# A33G53x register map
Vendor: ABOV Semiconductor Co., Ltd.; File version: 0.1
CPU: CM3 r1p0, little endian, no MPU, no FPU, 3 interrupt priority bits
Registers are 32-bit, read-write, reset 0x0 unless marked. A register's access mark holds for its fields unless they carry their own. Offsets are from the block's base; [hi:lo] are bit positions; {n}, {i} and the like mark numbered series.

## UART0 — UNIVERSAL ASYNCHRONOUS RECEIVER/TRANSMITTER
Base 0x40000B00
Same registers: UART1 0x40000B40, UART2 0x40000B80, UART3 0x40000BC0
0x00 RBR — Rx Buffer REGISTER
  [7:0] RBR — Received data byte
0x00 THR (alternate view of RBR) — Tx Buffer REGISTER
  [7:0] THR — Data byte to be transmitted
0x00 DLL (alternate view of RBR) — UART n Divisor Latch Register LSB
  [7:0] DLL
0x04 DLM (reset mask 0xF) — UART n Divisor Latch Register MSB
  [7:0] DLM
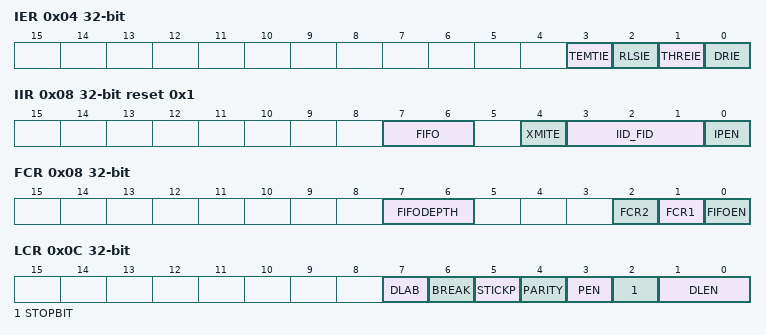
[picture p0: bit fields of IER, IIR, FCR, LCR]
0x04 IER (alternate view of DLM) — UART Interrupt Enable Register
  [3] TEMTIE — Transmission empty interrupt enable
  [2] RLSIE — receiver line status interrupt enable
  [1] THREIE — Transmit holding register empty interrupt enable
  [0] DRIE — Data Ready Interrupt Enable/Disable
0x08 IIR ro reset 0x1 (reset mask 0xCF) — UART Interrupt ID Register
  [7:6] FIFO — Current UART operation FIFO mode
  [4] XMITE — Transmit empty interrupt check
  [3:1] IID_FID — Interrupt source ID
  [0] IPEN — Interrupt pending bit
0x08 FCR wo — FIFO Control Register
  [7:6] FIFODEPTH — Receive FIFO trigger level
  [2] FCR2 — Initialize transmit FIFO
  [1] FCR1 — Initialize receive FIFO
  [0] FIFOEN — Enable transmit/receive FIFO
0x0C LCR — UART Line Control Register
  [7] DLAB — Norma Transmission-Divisor Latch Access Mode
  [6] BREAK — Normal Transmission-Send Break
  [5] STICKP — Stick Parity as L-H
  [4] PARITY — OddEven Parity
  [3] PEN — Enable Parity
  [2] STOPBIT — 1-(1.5,2) stop bits
  [1:0] DLEN — Data length in one transfer word
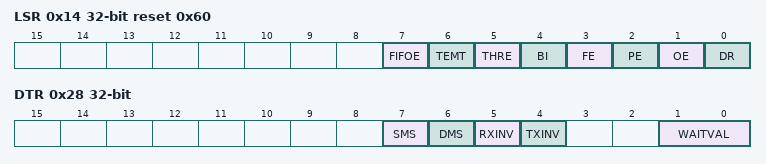
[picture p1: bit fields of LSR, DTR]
0x14 LSR reset 0x60 — UART Line Status Register
  [7] FIFOE ro — FIFO has invalid data
  [6] TEMT ro — Transmitter Empty
  [5] THRE ro — THR Empty
  [4] BI ro — break condition indication bit
  [3] FE ro — frame error
  [2] PE ro — parity error
  [1] OE ro — overrun error
  [0] DR ro — Data recevied
0x1C SCR — UART Scratch Register
  [7:0] SCR — This register is used to store a data temporarily by software programmer
0x24 BFR — UART BaudRate Fraction Counter Register
  [7:0] BFR — This 8-bit register is used to increase the accuracy of the baud rate.
0x28 DTR — UART Inter-frame Delay Time Register
  [7] SMS — Performs sampling of the start bit
  [6] DMS — Performs sampling of the Data bit
  [5] RXINV — Change / maintain external RX input
  [4] TXINV — Change / maintain TX Output
  [1:0] WAITVAL — Sets the delay time between successive data outputs

## SPI0 — SERIAL PERIPHERAL INTERFACE
Base 0x40000800
Same registers: SPI1 0x40000820
0x00 TDR — SPI n Transmit Data Register
  [16:0] TDR — Transmit Data Value
0x00 RDR (alternate view of TDR) — SPI n Receive Data Register
  [16:0] RDR — Receive Data Value
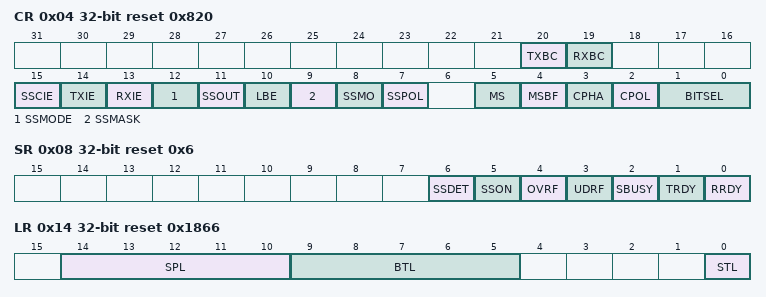
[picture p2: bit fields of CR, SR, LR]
0x04 CR reset 0x820 — SPI n Control Register
  [20] TXBC — TX BUFFER CLEAR
  [19] RXBC — RX BUFFER CLEAR
  [15] SSCIE — SSn Edge Chagne Interrupt enable bit
  [14] TXIE — Transmit interrupt enable bit
  [13] RXIE — Receive interrupt enable bit
  [12] SSMODE — SS Auto/Manual Output select bit
  [11] SSOUT — SS output signal select bit
  [10] LBE — Loop-back mode select bit in master mode
  [9] SSMASK — SS Signal masking bit in slave mode
  [8] SSMO — SS output signal select bit
  [7] SSPOL — SS Signal polarity select bit
  [5] MS — master/slaver select bit
  [4] MSBF — MSB/LSB transmit select bit
  [3] CPHA — SPI clock phase bit
  [2] CPOL — SPI clock polarity bit
  [1:0] BITSEL — Transmit/receive Data bits select bit
0x08 SR reset 0x6 — SPI n Status Register
  [6] SSDET — The rising edge of SS detect flag
  [5] SSON ro — SS signal status flag
  [4] OVRF — receive overrun error flag
  [3] UDRF — transmit underrun error flag
  [2] SBUSY ro — transmit/receive operation flag
  [1] TRDY ro — Transmit buffer empty flag
  [0] RRDY ro — receive buffer ready flag
0x0C BR — SPI n Baud Rate Register
  [7:0] BR — buadrate
0x10 EN — SPI n Enable register
  [0] ENABLE — SPI ENABLE bit
0x14 LR reset 0x1866 (reset mask 0x1FFF) — SPI n Timing register
  [14:10] SPL — Stop delay time setting
  [9:5] BTL — Burst delay time setting
  [0] STL — Start delay time setting

## ADC — 12-BIT A/D CONVERTER
Base 0x40000E00
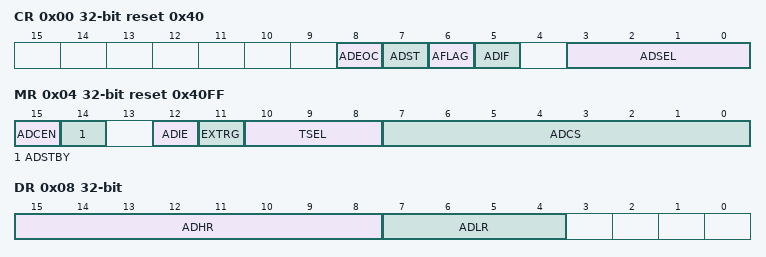
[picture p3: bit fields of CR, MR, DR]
0x00 CR reset 0x40 — ADC Control Register
  [8] ADEOC ro — A/D Conversion Status (Read/Only)
  [7] ADST — A/D Conversion Start
  [6] AFLAG — A/D Conversion Status Flag (Read-Only)
  [5] ADIF — A/D Converter interrupt Flag
  [3:0] ADSEL — Select ADC input channel(0~15)
0x04 MR reset 0x40FF — ADC Mode Register
  [15] ADCEN — Select ADC Enable
  [14] ADSTBY — Select ADC Stand-by mode
  [12] ADIE — Select End-of-Conversion interrupt
  [11] EXTRG — Select external trigger condition for start conversion
  [10:8] TSEL — SOC trigger source
  [7:0] ADCS — Select A/D conversion clock
0x08 DR ro — A/D Data Register
  [15:8] ADHR — Upper byte of A/D conversion data
  [7:4] ADLR — Lower byte of A/D conversion data

## MEMCR — Memory Control Register
Base 0x400000E0
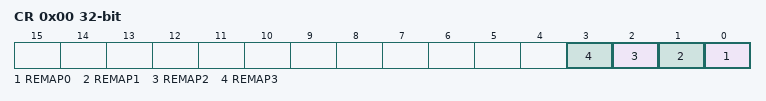
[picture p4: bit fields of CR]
0x00 CR — Memory Control Register
  [n] REMAP{n} (n=0..3) — Remap {0x0+0x1000*n} ~ {0xFFF+0x1000*n} Area (Area {n})

## LEGACY — PMULEGACY A33G53x Extended Mode Register
Base 0x400000F8
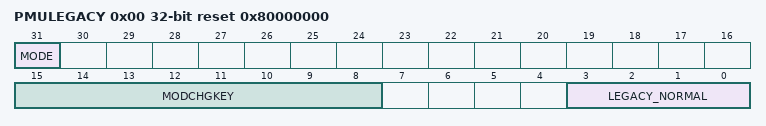
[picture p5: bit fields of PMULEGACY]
0x00 PMULEGACY reset 0x80000000 — PMULEGACY A33G53x Extended Mode Register
  [31] MODE ro — Mode Status Bit
  [15:8] MODCHGKEY wo — Mode Change Key
  [3:0] LEGACY_NORMAL — Legacy_Normal mode change
